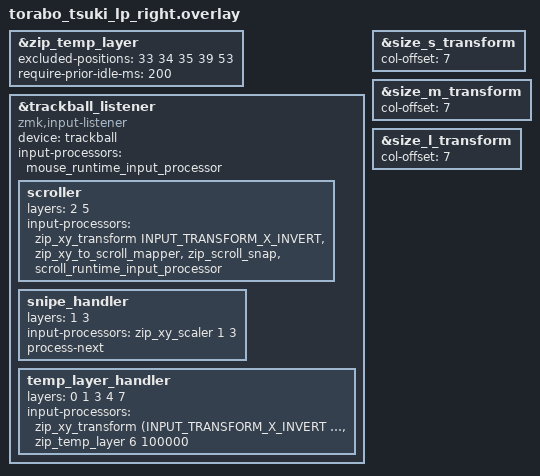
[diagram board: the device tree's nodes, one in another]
#include "torabo_tsuki_lp.dtsi"
#include <input/processors.dtsi>
#include <dt-bindings/zmk/input_transform.h>
#include <input/processors/runtime-input-processor.dtsi>
#include <scroll-snap.dtsi>

&zip_temp_layer {
    excluded-positions = <
        33 // j
        34 // k
        35 // l
        39 // shift
        53 // ctrl
    >;
    require-prior-idle-ms = <200>;
};

&trackball_listener {
    compatible = "zmk,input-listener";
    device = <&trackball>;
    input-processors = <
        &mouse_runtime_input_processor
    >;

    scroller {
        layers = <2 5>;
        input-processors = <
            &zip_xy_transform INPUT_TRANSFORM_X_INVERT
            &zip_xy_to_scroll_mapper
            &zip_scroll_snap
            &scroll_runtime_input_processor
        >;
    };

    /* レイヤー2：スナイプ（微調整） */
    snipe_handler {
        layers = <1 3>;
        input-processors =
            <&zip_xy_scaler 1 3>;
        process-next;
    };

    /* オートマウス一時レイヤー */
    temp_layer_handler {
        layers = <0 1 3 4 7>;
        input-processors = <
            &zip_xy_transform (INPUT_TRANSFORM_X_INVERT | INPUT_TRANSFORM_Y_INVERT)
            &zip_temp_layer 6 100000
        >;
    };
};


&size_s_transform {
    col-offset = <7>;
};

&size_m_transform {
    col-offset = <7>;
};

&size_l_transform {
    col-offset = <7>;
};
